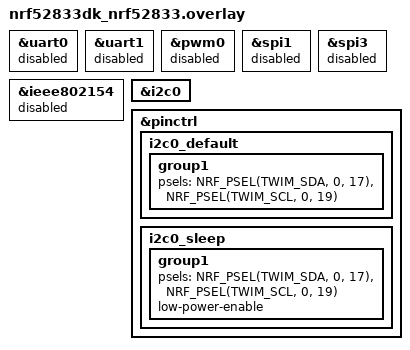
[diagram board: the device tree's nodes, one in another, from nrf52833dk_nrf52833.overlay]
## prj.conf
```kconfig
# enable SoC DC/DC for better power consumption (default y)
CONFIG_BOARD_ENABLE_DCDC=y

# enable Floating Point Unit (default n?)
CONFIG_FPU=y
# enable FPU sharing (multiple threads at once can use FPU)
CONFIG_FPU_SHARING=y

#CONFIG_CONSOLE=y
#CONFIG_USE_SEGGER_RTT=y
#CONFIG_RTT_CONSOLE=y
#CONFIG_LOG=y
#CONFIG_LOG_SPEED=y

CONFIG_I2C=y

# for math
CONFIG_NEWLIB_LIBC=y

CONFIG_BT=y
CONFIG_BT_PERIPHERAL=y
CONFIG_BT_DEVICE_NAME="TTPMS Internal Sensor"
CONFIG_BT_DEVICE_NAME_DYNAMIC=y
#CONFIG_BT_DEVICE_NAME_MAX default is 28 chars which will be fine
CONFIG_BT_DEVICE_APPEARANCE=1362

CONFIG_BT_BUF_ACL_TX_SIZE=251
CONFIG_BT_BUF_ACL_RX_SIZE=251
CONFIG_BT_L2CAP_TX_MTU=247
CONFIG_BT_CTLR_DATA_LENGTH_MAX=251

# set TX power to max (+8dB)
CONFIG_BT_CTLR_TX_PWR_PLUS_8=y
```

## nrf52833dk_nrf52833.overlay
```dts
// To get started, press Ctrl+Space to bring up the completion menu and view the available nodes.

// You can also use the buttons in the sidebar to perform actions on nodes.
// Actions currently available include:

// * Enabling / disabling the node
// * Adding the bus to a bus
// * Removing the node
// * Connecting ADC channels

// For more help, browse the DeviceTree documentation at https://docs.zephyrproject.org/latest/guides/dts/index.html
// You can also visit the nRF DeviceTree extension documentation at https://nrfconnect.github.io/vscode-nrf-connect/devicetree/nrfdevicetree.html


/* disabling all unused peripherals */

&uart0 {
    status = "disabled";
};

&uart1 {
    status = "disabled";
};

&pwm0 {
    status = "disabled";
};

&spi1 {
    status = "disabled";
};

&spi3 {
    status = "disabled";
};

&ieee802154 {
    status = "disabled";
};


/* configuring peripherals we will use  */

&i2c0 {
    status = "okay";
};

// ADC etc

&pinctrl {
    i2c0_default: i2c0_default {
		group1 {
			psels = <NRF_PSEL(TWIM_SDA, 0, 17)>,
				    <NRF_PSEL(TWIM_SCL, 0, 19)>;    // ttpms_is_2_0 uses P0.14 but this is an LED on the DK
		};
	};

	i2c0_sleep: i2c0_sleep {
		group1 {
			psels = <NRF_PSEL(TWIM_SDA, 0, 17)>,
				    <NRF_PSEL(TWIM_SCL, 0, 19)>;    // ttpms_is_2_0 uses P0.14 but this is an LED on the DK
			low-power-enable;
		};
	};
};
```

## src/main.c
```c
/* includes that will always be required */
#include <zephyr/kernel.h>
#include <zephyr/types.h>
#include <stddef.h>
#include <errno.h>
#include <zephyr/bluetooth/bluetooth.h>
#include <zephyr/bluetooth/hci.h>
#include <zephyr/bluetooth/conn.h>
#include <zephyr/bluetooth/uuid.h>
#include <zephyr/bluetooth/gatt.h>
#include <zephyr/drivers/gpio.h>
#include <math.h>

#include "ttpms_common.h"
#include "I2C_Functions.h"
#include "MLX90641_API.h"

/* includes for debugging/temporary */
#include <zephyr/logging/log.h>

LOG_MODULE_REGISTER(ttpms);


// IMPORTANT: define which corner the sensor will go
// options = TTPMS_IFL, TTPMS_IFR, TTPMS_IRL, TTPMS_IRR
#define TTPMS_IFL


// frequency of temp sensor updates (0x00 = 0.5Hz, 0x01 = 1Hz, 0x02 = 2Hz, 0x03 = 4Hz, 0x04 = 8Hz, 0x05 = 16Hz (default), 0x06 = 32Hz, 0x07 = 64Hz)
// Unlike the MLX90640, each MLX90641 subpage contains new data for every pixel
// have not tested max refresh rate with MLX90641 yet
// best way for more speed is to modify the MLX90641_API.c functions to only read and process relevant pixels
#define TEMP_FREQ 0x04


// haven't tuned these
#define TEMP_THREAD_STACKSIZE 8192
#define TEMP_THREAD_PRIORITY 4

void temp_thread(void *dummy1, void *dummy2, void *dummy3);
K_THREAD_STACK_DEFINE(temp_stack_area, TEMP_THREAD_STACKSIZE);
struct k_thread temp_thread_data;
k_tid_t temp_thread_id;


// How we keep track of state.
// Use Zephyr atomic set, clear, test functions.
ATOMIC_DEFINE(flags, 2);
#define TEMP_ENABLED_FLAG		0
#define PRESSURE_ENABLED_FLAG	1


// The actual temp data we will send to receiver
// Temp values have 0.5 scale, 0 offset (ie 0xAF = 175 = 87.5 C)
uint8_t tire_temp[16];


// Tune the below with testing
const float ta_shift = 8;		// Default shift for MLX90641 in open air
const float emissivity = 0.95;


static float mlx90641To[192];	// Processed temp data from MLX functions
paramsMLX90641 mlx90641;		// Used for MLX functions

float Vdd;	// From MLX, used by MLX functions
float Ta;	// From MLX, used by MLX functions


static const struct gpio_dt_spec mlx_power =
	GPIO_DT_SPEC_GET_OR(DT_NODELABEL(mlx_power), gpios, {0});



/* --- BLUETOOTH STUFF START --- */

#define BLE_ADV_INTERVAL_MIN 1200	// 1200 * 0.625ms = 0.75s
#define BLE_ADV_INTERVAL_MAX 2000	// 2000 * 0.625ms = 1.25s

#ifdef TTPMS_IFL
	#define TTPMS_SENSOR_BT_ID TTPMS_IFL_BT_ID
	char bt_device_name[28] = "TTPMS Internal Sensor FL";
#endif
#ifdef TTPMS_IFR
	#define TTPMS_SENSOR_BT_ID TTPMS_IFR_BT_ID
	char bt_device_name[28] = "TTPMS Internal Sensor FR";
#endif
#ifdef TTPMS_IRL
	#define TTPMS_SENSOR_BT_ID TTPMS_IRL_BT_ID
	char bt_device_name[28] = "TTPMS Internal Sensor RL";
#endif
#ifdef TTPMS_IRR
	#define TTPMS_SENSOR_BT_ID TTPMS_IRR_BT_ID
	char bt_device_name[28] = "TTPMS Internal Sensor RR";
#endif


static struct bt_uuid_128 primary_service_uuid = BT_UUID_INIT_128(TTPMS_SERVICE_BASE_UUID);
static struct bt_uuid_128 temp_characteristic_uuid = BT_UUID_INIT_128(TTPMS_SERVICE_TEMP_UUID);


static struct bt_le_adv_param adv_param;

static struct bt_conn *connection;


// this is a callback for if CCC is changed (could be subscribe or unsubscribe)
static void subscribe_temp(const struct bt_gatt_attr *attr, uint16_t value)
{
	const bool notif_enabled = (value == BT_GATT_CCC_NOTIFY);	// not sure why this is assigned to this of just checked in the if()

	if (notif_enabled) {	
		atomic_set_bit(flags, TEMP_ENABLED_FLAG);	// enable temperature measurements and start temp thread
		temp_thread_id = k_thread_create(&temp_thread_data, temp_stack_area,
                                 K_THREAD_STACK_SIZEOF(temp_stack_area),
                                 temp_thread,
                                 NULL, NULL, NULL,
                                 TEMP_THREAD_PRIORITY, 0, K_NO_WAIT);
		LOG_INF("Notifications subscribed, temp enabled");
	} else {
		atomic_clear_bit(flags, TEMP_ENABLED_FLAG); // disable temperature measurements
		LOG_INF("Notifications unsubscribed, temp disabled");
	}
}


// GATT table declaration
BT_GATT_SERVICE_DEFINE(primary_service,
	BT_GATT_PRIMARY_SERVICE(&primary_service_uuid),
		BT_GATT_CHARACTERISTIC(&temp_characteristic_uuid.uuid, BT_GATT_CHRC_NOTIFY, NULL, NULL, NULL, NULL),
			BT_GATT_CCC(subscribe_temp, BT_GATT_PERM_READ | BT_GATT_PERM_WRITE),
);

static const struct bt_data ad[] = {
	BT_DATA_BYTES(BT_DATA_FLAGS, (BT_LE_AD_GENERAL | BT_LE_AD_NO_BREDR)),
	BT_DATA_BYTES(BT_DATA_UUID128_ALL, TTPMS_SERVICE_BASE_UUID),
};

static void connected(struct bt_conn *conn, uint8_t err)
{
	if (err) {
		LOG_WRN("Connection failed (err 0x%02x)", err);
	} else {
		LOG_INF("Connected");
		connection = conn;
	}
}

static void disconnected(struct bt_conn *conn, uint8_t reason)
{
	LOG_INF("Disconnected (reason 0x%02x)", reason);
	atomic_clear_bit(flags, TEMP_ENABLED_FLAG);	// disable temperature measurements
	connection = NULL;
}

BT_CONN_CB_DEFINE(conn_callbacks) = {
	.connected = connected,
	.disconnected = disconnected
};

/* --- BLUETOOTH STUFF END --- */


void main(void)
{
	LOG_INF("Running ttpms_v2_internal build for %s", CONFIG_BOARD);

	int err;
	
	if (!gpio_is_ready_dt(&mlx_power)) {
		LOG_ERR("The load switch pin GPIO port is not ready.");
		return;
	}

	err = gpio_pin_configure_dt(&mlx_power, GPIO_OUTPUT_INACTIVE);
	if (err != 0) {
		LOG_ERR("Configuring GPIO pin failed: %d", err);
		return;
	}

	bt_addr_le_t addr;

	err = bt_addr_le_from_str(TTPMS_SENSOR_BT_ID, "random", &addr);
	if (err) {
		LOG_ERR("Invalid BT address (err %d)", err);
	}

	err = bt_id_create(&addr, NULL);
	if (err < 0) {
		LOG_ERR("Creating new BT ID failed (err %d)", err);
	}

	err = bt_enable(NULL);
	if (err) {
		LOG_ERR("Bluetooth init failed (err %d)", err);
	} else {
		LOG_INF("Bluetooth initialized");
	}

	err = bt_set_name(bt_device_name);
	if (err) {
		LOG_ERR("Failed to set BT Device name (err %d)", err);
	} else {
		LOG_INF("Successfully set BT device name");
	}

	adv_param = *BT_LE_ADV_CONN_NAME;
	adv_param.interval_min = BLE_ADV_INTERVAL_MIN;
	adv_param.interval_max = BLE_ADV_INTERVAL_MAX;

	err = bt_le_adv_start(&adv_param, ad, ARRAY_SIZE(ad), NULL, 0);
	if (err) {
		LOG_ERR("Advertising failed to start (err %d)", err);
	} else {
		LOG_INF("Advertising successfully started");
	}

}


void temp_thread(void *dummy1, void *dummy2, void *dummy3)
{
	ARG_UNUSED(dummy1);
	ARG_UNUSED(dummy2);
	ARG_UNUSED(dummy3);

	int status;

	status = gpio_pin_set_dt(&mlx_power, 1);	// turn on MLX power MOSFET
	if (status != 0) {
		LOG_ERR("Setting GPIO pin level failed: %d", status);
	}

	//k_sleep(K_MSEC(80));	// wait 80ms after MLX90641 POR, then:
	//k_sleep(K_MSEC(500));	// wait one refresh rate? default refresh rate?
	k_sleep(K_MSEC(1000));	//datasheet is weird so just wait 1 second to be safe

	uint16_t eeMLX90641[832];

	status = MLX90641_DumpEE(MLX90641_ADDR, eeMLX90641);
	if (status != 0) {
		LOG_ERR("Failed to load system parameters, MLX90641_DumpEE() returned %d", status);
	} else {
		LOG_INF("Dumped MLX EE");
	}

	status = MLX90641_ExtractParameters(eeMLX90641, &mlx90641);
	if (status != 0) {
		LOG_ERR("Parameter extraction failed, MLX90641_ExtractParameters() returned %d", status);
	} else {
		LOG_INF("Extracted MLX parameters");
	}

	status = MLX90641_SetRefreshRate(MLX90641_ADDR, TEMP_FREQ);
	if (status != 0) {
		LOG_ERR("Setting refresh rate failed, MLX90641_SetRefreshRate() returned %d", status);
	} else {
		LOG_INF("Set MLX refresh rate");
	}

	status = MLX90641_SynchFrame(MLX90641_ADDR);
	if (status != 0) {
		LOG_ERR("Synchronizing MLX frame failed, MLX90641_SynchFrame() returned %d", status);
	} else {
		LOG_INF("Synchronized MLX frame");
	}

	
	while (atomic_test_bit(flags, TEMP_ENABLED_FLAG))	// atomic babbyyyy
	{

		uint16_t frame[242];

		status = MLX90641_GetFrameData(MLX90641_ADDR, frame);	// this function waits until data is available from MLX
		if (status < 0) {
			LOG_ERR("Getting MLX frame data failed, MLX90641_GetFrameData() returned %d", status);
		}

		Vdd = MLX90641_GetVdd(frame, &mlx90641);

		Ta = MLX90641_GetTa(frame, &mlx90641);

		float tr = Ta - ta_shift; // Reflected temperature based on the sensor ambient temperature

		//LOG_INF("started temp processing");
		MLX90641_CalculateTo(frame, &mlx90641, emissivity, tr, mlx90641To);
		//LOG_INF("finished temp processing");

		for (int i = 0; i < 16; i++)
		{
			tire_temp[i] = CLAMP(round((mlx90641To[64+i]+mlx90641To[80+i]+mlx90641To[96+i]+mlx90641To[112+i])/2), 0, 255);
		}
		
		//LOG_INF("First pixel: %.1f 16th pixel: %.1f, ((float)tire_temp[0]/2), ((float)tire_temp[15]/2));

		if((connection != NULL) && atomic_test_bit(flags, TEMP_ENABLED_FLAG)) {	// MLX processing above takes a while, check if we are still connected and temp is enabled
			status = bt_gatt_notify(connection, &primary_service.attrs[1], &tire_temp, sizeof(tire_temp));
			if(status != 0) {
				LOG_ERR("Failed to notify, bt_gatt_notify returned: %d", status);
			} else {
				//LOG_INF("Notified");
			}
		}
	}

	status = gpio_pin_set_dt(&mlx_power, 0);	// turn off MLX power MOSFET
	if (status != 0) {
		LOG_ERR("Setting GPIO pin level failed: %d", status);
	}

}
```

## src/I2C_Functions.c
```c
#include "I2C_Functions.h"
#include <zephyr/kernel.h>
#include <zephyr/device.h>
#include <zephyr/drivers/i2c.h>
#include <errno.h>

/* includes for debugging/temporary */
#include <zephyr/logging/log.h>

LOG_MODULE_DECLARE(ttpms);

const struct device *const i2c_dev = DEVICE_DT_GET(DT_NODELABEL(i2c0)); // is something like "chosen" in devicetree for I2C (see how CAN device is done)


int I2C_Init()  // this doesn't actually init anything lol
{   
    if(!device_is_ready(i2c_dev)) {
        return -1;
    } else {
        return 0;
    }
    //i2c_configure should be uneccessary since we set 400KHz in devicetree
}

int I2C_GeneralReset(void)  // this function is originally for MLX one-shot mode, will not be used
{    
    int ack;
    uint8_t cmd = 0x06;   
 
    // writing 0x06 to address 0x00 will reset all devices on I2C
    ack = i2c_write(i2c_dev, &cmd, 1, 0x00);

    if (ack != 0x00)
    {
        LOG_ERR("Error sending I2C reset message");
        return -1;
    }         

    return 0;
}

int MLX_I2CRead(uint8_t slaveAddr, uint16_t startAddress, uint16_t nMemAddressRead, uint16_t *data)
{                          
    int ack = 0;                               
    int cnt = 0;
    int i = 0;
    char cmd[2] = {0,0};
    char i2cData[1664] = {0};
    uint16_t *p;

    p = data;
    cmd[0] = startAddress >> 8;
    cmd[1] = startAddress & 0x00FF;

    ack = i2c_write_read(i2c_dev, slaveAddr, cmd, 2, i2cData, 2*nMemAddressRead);

    if (ack != 0x00)
    {
        LOG_ERR("Error reading from MLX over I2C");
        return -1;
    }

    for(cnt=0; cnt < nMemAddressRead; cnt++)    // this just turns uint8_t[2*nMemAddressRead] into uint16_t[nMemAddressRead]
    {
        i = cnt << 1;
        *p++ = (uint16_t)i2cData[i]*256 + (uint16_t)i2cData[i+1];
    }

    return 0;   
} 

int MLX_I2CWrite(uint8_t slaveAddr, uint16_t writeAddress, uint16_t data)
{
    int ack = 0;
    char cmd[4] = {0,0,0,0};
    static uint16_t dataCheck;

    cmd[0] = writeAddress >> 8;
    cmd[1] = writeAddress & 0x00FF;
    cmd[2] = data >> 8;
    cmd[3] = data & 0x00FF;

    //k_sleep(K_USEC(5));

    ack = i2c_write(i2c_dev, cmd, 4, slaveAddr);

    if (ack != 0x00)
    {
        //LOG_ERR("Error writing to MLX over I2C");
        return -1;
    }         

    MLX_I2CRead(slaveAddr, writeAddress, 1, &dataCheck);

    if (dataCheck != data)
    {
        //LOG_ERR("Error writing to MLX, readback failed");
        //LOG_ERR("dataCheck: %d  data: %d", dataCheck, data);
        return -2;
    }    

    return 0;
}
```

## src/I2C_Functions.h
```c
#ifndef _I2C_Functions_H_
#define _I2C_Functions_H_

#include <stdint.h>

    extern int I2C_Init(void);
    extern int I2C_GeneralReset(void);
    extern int MLX_I2CRead(uint8_t slaveAddr,uint16_t startAddress, uint16_t nMemAddressRead, uint16_t *data);
    extern int MLX_I2CWrite(uint8_t slaveAddr,uint16_t writeAddress, uint16_t data);
    
    #define MLX90641_ADDR   0x33
    #define MLX90640_ADDR   0x33
    #define MLX90621_ADDR   0x60

#endif
```

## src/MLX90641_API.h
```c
/**
 * @copyright (C) 2017 Melexis N.V.
 *
 * Licensed under the Apache License, Version 2.0 (the "License");
 * you may not use this file except in compliance with the License.
 * You may obtain a copy of the License at
 *
 *     http://www.apache.org/licenses/LICENSE-2.0
 *
 * Unless required by applicable law or agreed to in writing, software
 * distributed under the License is distributed on an "AS IS" BASIS,
 * WITHOUT WARRANTIES OR CONDITIONS OF ANY KIND, either express or implied.
 * See the License for the specific language governing permissions and
 * limitations under the License.
 *
 */
#ifndef _MLX90641_API_H_
#define _MLX90641_API_H_

#define SCALEALPHA 0.000001
    
  typedef struct
    {
        int16_t kVdd;
        int16_t vdd25;
        float KvPTAT;
        float KtPTAT;
        uint16_t vPTAT25;
        float alphaPTAT;
        int16_t gainEE;
        float tgc;
        float cpKv;
        float cpKta;
        uint8_t resolutionEE;
        uint8_t calibrationModeEE;
        float KsTa;
        float ksTo[8];
        int16_t ct[8];
        uint16_t alpha[192]; 
        uint8_t alphaScale;   
        int16_t offset[2][192];    
        int8_t kta[192];
        uint8_t ktaScale;    
        int8_t kv[192];
        uint8_t kvScale;
        float cpAlpha;
        int16_t cpOffset;
        float emissivityEE; 
        uint16_t brokenPixel;
    } paramsMLX90641;
    
    int MLX90641_DumpEE(uint8_t slaveAddr, uint16_t *eeData);
    int MLX90641_SynchFrame(uint8_t slaveAddr);
    //int MLX90641_TriggerMeasurement(uint8_t slaveAddr); We will not be using one shot mode since it would also reset the I2C pressure sensor
    int MLX90641_GetFrameData(uint8_t slaveAddr, uint16_t *frameData);
    int MLX90641_ExtractParameters(uint16_t *eeData, paramsMLX90641 *mlx90641);
    float MLX90641_GetVdd(uint16_t *frameData, const paramsMLX90641 *params);
    float MLX90641_GetTa(uint16_t *frameData, const paramsMLX90641 *params);
    void MLX90641_GetImage(uint16_t *frameData, const paramsMLX90641 *params, float *result);
    void MLX90641_CalculateTo(uint16_t *frameData, const paramsMLX90641 *params, float emissivity, float tr, float *result);
    int MLX90641_SetResolution(uint8_t slaveAddr, uint8_t resolution);
    int MLX90641_GetCurResolution(uint8_t slaveAddr);
    int MLX90641_SetRefreshRate(uint8_t slaveAddr, uint8_t refreshRate);   
    int MLX90641_GetRefreshRate(uint8_t slaveAddr);  
    int MLX90641_GetSubPageNumber(uint16_t *frameData);
    float MLX90641_GetEmissivity(const paramsMLX90641 *mlx90641);
    void MLX90641_BadPixelsCorrection(uint16_t pixel, float *to);
    
#endif
```

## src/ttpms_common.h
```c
#ifndef _TTPMS_COMMON_
#define _TTPMS_COMMON_

// BLE addresses/identities
// First hex char must be C for random static address (to self-assign identity)

#define TTPMS_RX_BT_ID  "CA:69:F1:F1:69:69"		// Receiver BT ID
#define TTPMS_IFL_BT_ID "CA:69:F1:F1:33:42"		// Internal Front Left BT ID
#define TTPMS_IFR_BT_ID "CA:69:F1:F1:33:43"		// Internal Front Right BT ID
#define TTPMS_IRL_BT_ID "CA:69:F1:F1:33:44"		// Internal Rear Left BT ID
#define TTPMS_IRR_BT_ID "CA:69:F1:F1:33:45"		// Internal Rear Right BT ID
#define TTPMS_EFL_BT_ID "CA:69:F1:F1:11:22"		// External Front Left BT ID
#define TTPMS_EFR_BT_ID "CA:69:F1:F1:11:23"		// External Front Right BT ID
#define TTPMS_ERL_BT_ID "CA:69:F1:F1:11:24"		// External Rear Left BT ID
#define TTPMS_ERR_BT_ID "CA:69:F1:F1:11:25"		// External Rear Right BT ID


// BLE UUIDs
// In theory it should be ok that each sensor shares the same GATT service UUIDs,
// since the receiver distinguishes between them based on BT address/identity.

#define TTPMS_BASE_UUID_PART_1	0x3022c87e
#define TTPMS_BASE_UUID_PART_2	0x71b0
#define TTPMS_BASE_UUID_PART_3	0x4d57
#define TTPMS_BASE_UUID_PART_4	0x881f
#define TTPMS_BASE_UUID_PART_5	0x54996ce814ad


// Base UUID, randomly generated, used for the overall GATT service
#define TTPMS_SERVICE_BASE_UUID BT_UUID_128_ENCODE(	TTPMS_BASE_UUID_PART_1, \
													TTPMS_BASE_UUID_PART_2, \
													TTPMS_BASE_UUID_PART_3, \
													TTPMS_BASE_UUID_PART_4, \
													TTPMS_BASE_UUID_PART_5		)

// Base UUID + 1, used for the battery life GATT characteristic
#define TTPMS_SERVICE_BATT_UUID BT_UUID_128_ENCODE(	TTPMS_BASE_UUID_PART_1, \
													TTPMS_BASE_UUID_PART_2, \
													TTPMS_BASE_UUID_PART_3, \
													TTPMS_BASE_UUID_PART_4, \
													TTPMS_BASE_UUID_PART_5 + 1	)

// Base UUID + 2, used for the temperature GATT characteristic
#define TTPMS_SERVICE_TEMP_UUID BT_UUID_128_ENCODE(	TTPMS_BASE_UUID_PART_1, \
													TTPMS_BASE_UUID_PART_2, \
													TTPMS_BASE_UUID_PART_3, \
													TTPMS_BASE_UUID_PART_4, \
													TTPMS_BASE_UUID_PART_5 + 2	)

// Base UUID + 3, used for the pressure GATT characteristic
#define TTPMS_SERVICE_PRES_UUID BT_UUID_128_ENCODE(	TTPMS_BASE_UUID_PART_1, \
													TTPMS_BASE_UUID_PART_2, \
													TTPMS_BASE_UUID_PART_3, \
													TTPMS_BASE_UUID_PART_4, \
													TTPMS_BASE_UUID_PART_5 + 3	)

#endif
```
